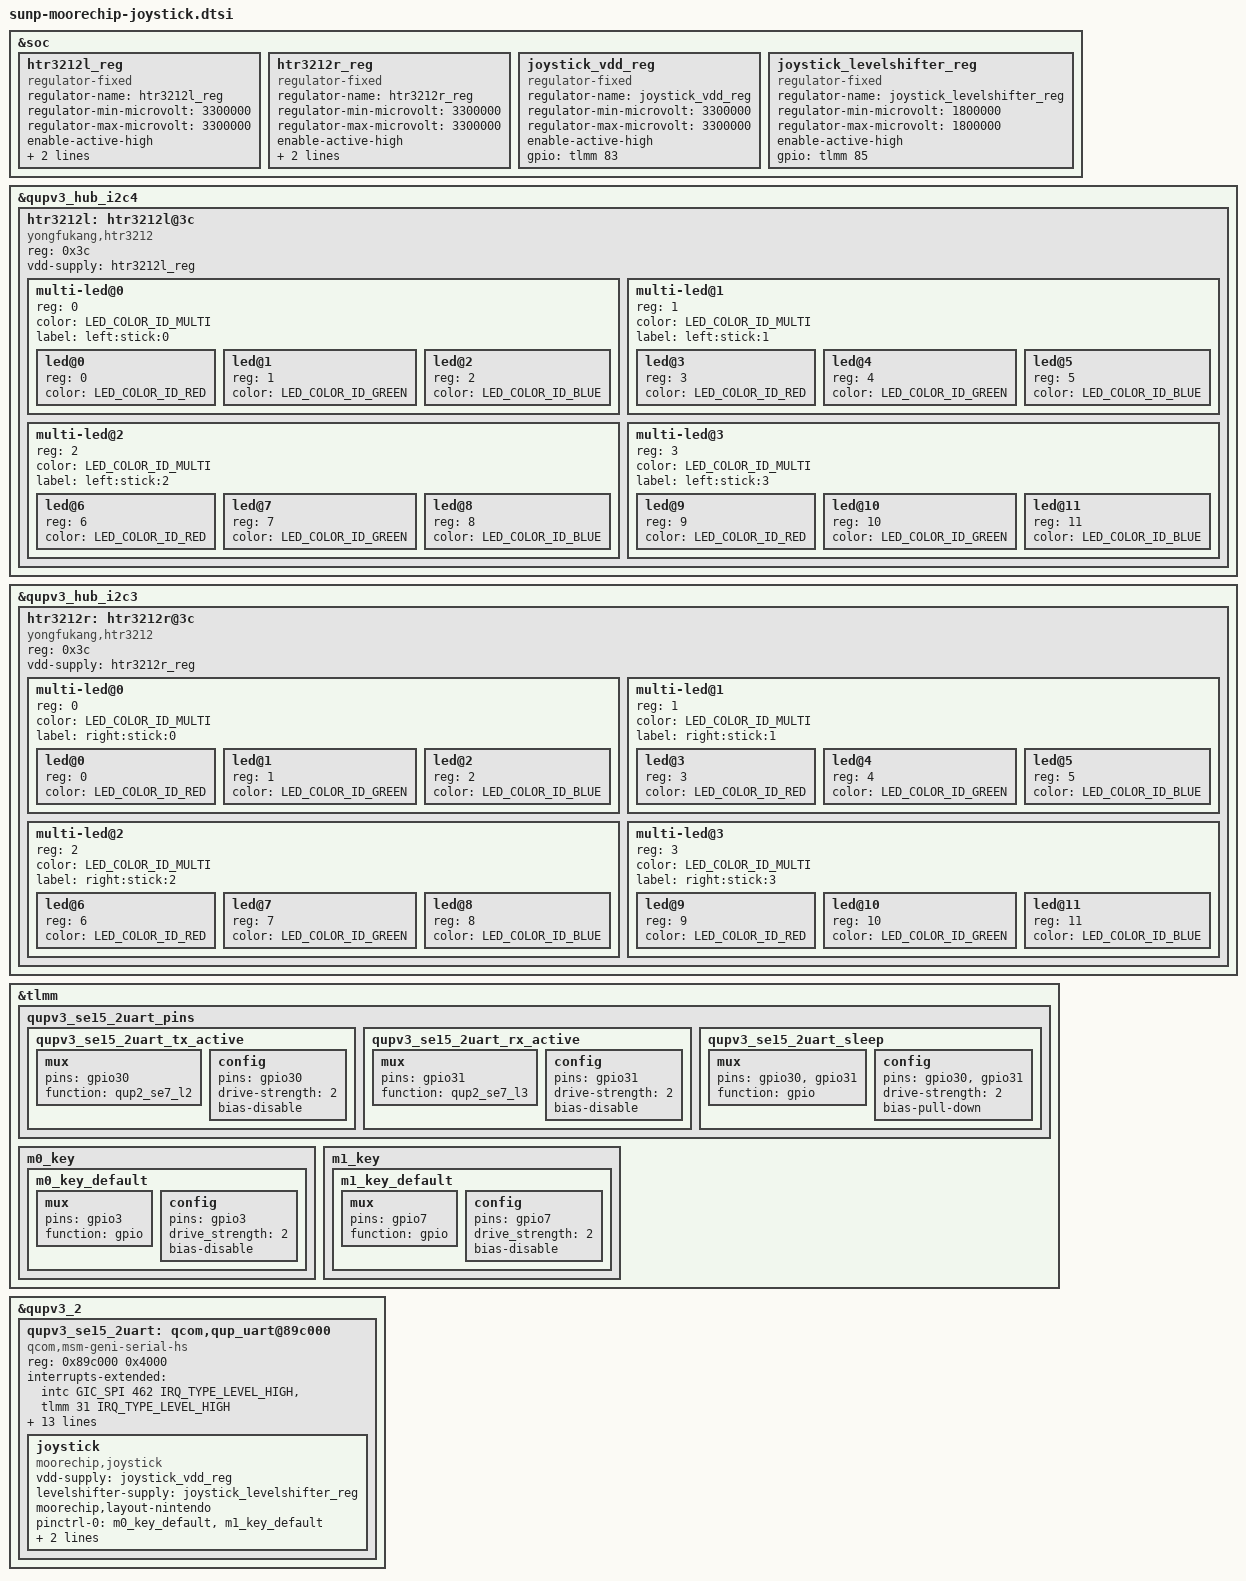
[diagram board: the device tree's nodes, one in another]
#include <dt-bindings/clock/qcom,gcc-sun.h>
#include <dt-bindings/interconnect/qcom,sun.h>
#include <dt-bindings/interrupt-controller/arm-gic.h>
#include <dt-bindings/leds/common.h>

&soc {
	htr3212l_reg: htr3212l_reg {
		compatible = "regulator-fixed";
		regulator-name = "htr3212l_reg";
		regulator-min-microvolt = <3300000>;
		regulator-max-microvolt = <3300000>;
		enable-active-high;
		gpio = <&tlmm 87 GPIO_ACTIVE_HIGH>;
    	vin-supply = <&joystick_vdd_reg>;
	};
};

&qupv3_hub_i2c4 {
	#address-cells = <1>;
	#size-cells = <0>;
	status = "ok";

	htr3212l: htr3212l@3c {
		compatible = "yongfukang,htr3212";
		reg = <0x3c>;
		vdd-supply = <&htr3212l_reg>;

		multi-led@0 {
			#address-cells = <1>;
			#size-cells = <0>;
			reg = <0>;
			color = <LED_COLOR_ID_MULTI>;
			label = "left:stick:0";

			led@0 {
				reg = <0>;
				color = <LED_COLOR_ID_RED>;
			};

			led@1 {
				reg = <1>;
				color = <LED_COLOR_ID_GREEN>;
			};

			led@2 {
				reg = <2>;
				color = <LED_COLOR_ID_BLUE>;
			};
		};

		multi-led@1 {
			#address-cells = <1>;
			#size-cells = <0>;
			reg = <1>;
			color = <LED_COLOR_ID_MULTI>;
			label = "left:stick:1";

			led@3 {
				reg = <3>;
				color = <LED_COLOR_ID_RED>;
			};

			led@4 {
				reg = <4>;
				color = <LED_COLOR_ID_GREEN>;
			};

			led@5 {
				reg = <5>;
				color = <LED_COLOR_ID_BLUE>;
			};
		};

		multi-led@2 {
			#address-cells = <1>;
			#size-cells = <0>;
			reg = <2>;
			color = <LED_COLOR_ID_MULTI>;
			label = "left:stick:2";

			led@6 {
				reg = <6>;
				color = <LED_COLOR_ID_RED>;
			};

			led@7 {
				reg = <7>;
				color = <LED_COLOR_ID_GREEN>;
			};

			led@8 {
				reg = <8>;
				color = <LED_COLOR_ID_BLUE>;
			};
		};

		multi-led@3 {
			#address-cells = <1>;
			#size-cells = <0>;
			reg = <3>;
			color = <LED_COLOR_ID_MULTI>;
			label = "left:stick:3";

			led@9 {
				reg = <9>;
				color = <LED_COLOR_ID_RED>;
			};

			led@10 {
				reg = <10>;
				color = <LED_COLOR_ID_GREEN>;
			};

			led@11 {
				reg = <11>;
				color = <LED_COLOR_ID_BLUE>;
			};
		};
	};
};

&soc {
	htr3212r_reg: htr3212r_reg {
		compatible = "regulator-fixed";
		regulator-name = "htr3212r_reg";
		regulator-min-microvolt = <3300000>;
		regulator-max-microvolt = <3300000>;
		enable-active-high;
		gpio = <&tlmm 88 GPIO_ACTIVE_HIGH>;
    	vin-supply = <&joystick_vdd_reg>;
	};
};

&qupv3_hub_i2c3 {
	#address-cells = <1>;
	#size-cells = <0>;
	status = "ok";

	htr3212r: htr3212r@3c {
		compatible = "yongfukang,htr3212";
		reg = <0x3c>;
		vdd-supply = <&htr3212r_reg>;

		multi-led@0 {
			#address-cells = <1>;
			#size-cells = <0>;
			reg = <0>;
			color = <LED_COLOR_ID_MULTI>;
			label = "right:stick:0";

			led@0 {
				reg = <0>;
				color = <LED_COLOR_ID_RED>;
			};

			led@1 {
				reg = <1>;
				color = <LED_COLOR_ID_GREEN>;
			};

			led@2 {
				reg = <2>;
				color = <LED_COLOR_ID_BLUE>;
			};
		};

		multi-led@1 {
			#address-cells = <1>;
			#size-cells = <0>;
			reg = <1>;
			color = <LED_COLOR_ID_MULTI>;
			label = "right:stick:1";

			led@3 {
				reg = <3>;
				color = <LED_COLOR_ID_RED>;
			};

			led@4 {
				reg = <4>;
				color = <LED_COLOR_ID_GREEN>;
			};

			led@5 {
				reg = <5>;
				color = <LED_COLOR_ID_BLUE>;
			};
		};

		multi-led@2 {
			#address-cells = <1>;
			#size-cells = <0>;
			reg = <2>;
			color = <LED_COLOR_ID_MULTI>;
			label = "right:stick:2";

			led@6 {
				reg = <6>;
				color = <LED_COLOR_ID_RED>;
			};

			led@7 {
				reg = <7>;
				color = <LED_COLOR_ID_GREEN>;
			};

			led@8 {
				reg = <8>;
				color = <LED_COLOR_ID_BLUE>;
			};
		};

		multi-led@3 {
			#address-cells = <1>;
			#size-cells = <0>;
			reg = <3>;
			color = <LED_COLOR_ID_MULTI>;
			label = "right:stick:3";

			led@9 {
				reg = <9>;
				color = <LED_COLOR_ID_RED>;
			};

			led@10 {
				reg = <10>;
				color = <LED_COLOR_ID_GREEN>;
			};

			led@11 {
				reg = <11>;
				color = <LED_COLOR_ID_BLUE>;
			};
		};
	};
};

&soc {
	joystick_vdd_reg: joystick_vdd_reg {
		compatible = "regulator-fixed";
		regulator-name = "joystick_vdd_reg";
		regulator-min-microvolt = <3300000>;
		regulator-max-microvolt = <3300000>;
		enable-active-high;
		gpio = <&tlmm 83 GPIO_ACTIVE_HIGH>;
	};

	// AW3911
	joystick_levelshifter_reg: joystick_levelshifter_reg {
		compatible = "regulator-fixed";
		regulator-name = "joystick_levelshifter_reg";
		regulator-min-microvolt = <1800000>;
		regulator-max-microvolt = <1800000>;
		enable-active-high;
		gpio = <&tlmm 85 GPIO_ACTIVE_HIGH>;
	};
};

&tlmm {
	qupv3_se15_2uart_pins: qupv3_se15_2uart_pins {
		qupv3_se15_2uart_tx_active: qupv3_se15_2uart_tx_active {
			mux {
				pins = "gpio30";
				function = "qup2_se7_l2";
			};

			config {
				pins = "gpio30";
				drive-strength = <2>;
				bias-disable;
			};
		};

		qupv3_se15_2uart_rx_active: qupv3_se15_2uart_rx_active {
			mux {
				pins = "gpio31";
				function = "qup2_se7_l3";
			};

			config {
				pins = "gpio31";
				drive-strength = <2>;
				bias-disable;
			};
		};

		qupv3_se15_2uart_sleep: qupv3_se15_2uart_sleep {
			mux {
				pins = "gpio30", "gpio31";
				function = "gpio";
			};

			config {
				pins = "gpio30", "gpio31";
				drive-strength = <2>;
				bias-pull-down;
			};
		};
	};

	m0_key: m0_key {
		m0_key_default: m0_key_default {
			mux {
				pins = "gpio3";
				function = "gpio";
			};
			config {
				pins = "gpio3";
				drive_strength = <2>;
				bias-disable;
			};
		};
	};

	m1_key: m1_key {
		m1_key_default: m1_key_default {
			mux {
				pins = "gpio7";
				function = "gpio";
			};
			config {
				pins = "gpio7";
				drive_strength = <2>;
				bias-disable;
			};
		};
	};
};

&qupv3_2 {
	qupv3_se15_2uart: qcom,qup_uart@89c000 {
		compatible = "qcom,msm-geni-serial-hs";
		reg = <0x89c000 0x4000>;
		reg-names = "se_phys";
		interrupts-extended = <&intc GIC_SPI 462 IRQ_TYPE_LEVEL_HIGH>,
				<&tlmm 31 IRQ_TYPE_LEVEL_HIGH>;
		clock-names = "se-clk";
		clocks = <&gcc GCC_QUPV3_WRAP2_S7_CLK>;
		interconnect-names = "qup-core", "qup-config", "qup-memory";
		interconnects =
			<&clk_virt MASTER_QUP_CORE_2 &clk_virt SLAVE_QUP_CORE_2>,
			<&gem_noc MASTER_APPSS_PROC &config_noc SLAVE_QUP_2>,
			<&aggre2_noc MASTER_QUP_2 &mc_virt SLAVE_EBI1>;
		pinctrl-names = "default", "sleep", "shutdown";
		pinctrl-0 = <&qupv3_se15_2uart_tx_active &qupv3_se15_2uart_rx_active>;
		pinctrl-1 = <&qupv3_se15_2uart_sleep>;
		pinctrl-2 = <&qupv3_se15_2uart_tx_active &qupv3_se15_2uart_rx_active>;
		qcom,wakeup-byte = <0xfd>;
		qcom,auto-suspend-disable;
		status = "disabled";
	};
};

&qupv3_se15_2uart {
	status = "okay";

	joystick: joystick {
		status = "okay";
		compatible = "moorechip,joystick";
		vdd-supply = <&joystick_vdd_reg>;
		levelshifter-supply = <&joystick_levelshifter_reg>;

		moorechip,layout-nintendo;

		pinctrl-names = "default";
		pinctrl-0 = <&m0_key_default>, <&m1_key_default>;

		m0_key-gpio = <&tlmm 3 GPIO_ACTIVE_LOW>;
		m1_key-gpio = <&tlmm 7 GPIO_ACTIVE_LOW>;
	};
};
